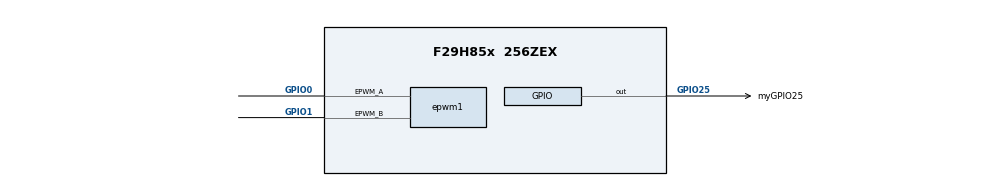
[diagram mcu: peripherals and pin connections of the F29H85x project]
/**
 * @cliArgs --device "F29H85x" --package "256ZEX" --part "F29H85x_256ZEX" --context "CPU1" --product "MCU_SDK_F29H85x@1.02.02.00"
 * @versions {"tool":"1.25.0+4237"}
 */

    
const divider15       = system.clockTree["PLL_REFDIV"];
divider15.divideValue = 1;

const multiplier1         = system.clockTree["PLL_IMULT"];
multiplier1.multiplyValue = 40;

const mux7       = system.clockTree["OSCCLKSRCSEL"];
mux7.inputSelect = "INTOSC2";

const epwm             = scripting.addModule("/driverlib/epwm.js", {}, false);
const epwm1            = epwm.addInstance();
const epwmxbar         = scripting.addModule("/driverlib/epwmxbar.js", {}, false);
const epwmxbar1        = epwmxbar.addInstance();
const gpio             = scripting.addModule("/driverlib/gpio.js", {}, false);
const gpio1            = gpio.addInstance();
const inputxbar_input  = scripting.addModule("/driverlib/inputxbar_input.js", {}, false);
const inputxbar_input1 = inputxbar_input.addInstance();

/**
 * Write custom configuration values to the imported modules.
 */
epwm1.$name                                                           = "myEPWM1";
epwm1.epwmTimebase_clockDiv                                           = "EPWM_CLOCK_DIVIDER_4";
epwm1.epwmTimebase_hsClockDiv                                         = "EPWM_HSCLOCK_DIVIDER_4";
epwm1.epwmTimebase_period                                             = 12000;
epwm1.epwmTimebase_counterMode                                        = "EPWM_COUNTER_MODE_UP_DOWN";
epwm1.epwmCounterCompare_cmpA                                         = 2000;
epwm1.epwmActionQualifier_EPWM_AQ_OUTPUT_A_ON_TIMEBASE_UP_CMPA        = "EPWM_AQ_OUTPUT_HIGH";
epwm1.epwmActionQualifier_EPWM_AQ_OUTPUT_A_ON_TIMEBASE_DOWN_CMPA      = "EPWM_AQ_OUTPUT_LOW";
epwm1.epwmActionQualifier_EPWM_AQ_OUTPUT_B_ON_TIMEBASE_UP_CMPA        = "EPWM_AQ_OUTPUT_HIGH";
epwm1.epwmActionQualifier_EPWM_AQ_OUTPUT_B_ON_TIMEBASE_DOWN_CMPA      = "EPWM_AQ_OUTPUT_LOW";
epwm1.epwmEventTrigger_enableInterrupt                                = true;
epwm1.epwmEventTrigger_registerInterrupts                             = true;
epwm1.epwmInt.interruptHandler                                        = "epwm1ISR";
epwm1.epwmEventTrigger_interruptSource                                = "EPWM_INT_TBCTR_ZERO";
epwm1.epwmEventTrigger_interruptEventCount                            = "3";
epwm1.epwmTripZone_cbcSource                                          = ["EPWM_TZ_SIGNAL_DCBEVT2"];
epwm1.epwmDigitalCompare_EPWM_TZ_DC_OUTPUT_B2                         = "EPWM_TZ_EVENT_DCXH_LOW";
epwm1.epwmDigitalCompare_dcFilterInput                                = "EPWM_DC_WINDOW_SOURCE_DCBEVT2";
epwm1.epwmDigitalCompare_useEdgeFilter                                = true;
epwm1.epwmDigitalCompare_edgeFilterEdgeCount                          = "EPWM_DC_EDGEFILT_EDGECNT_4";
epwm1.epwmDigitalCompare_enableValleyCapture                          = true;
epwm1.epwmDigitalCompare_valleyCaptureSource                          = "EPWM_VALLEY_TRIGGER_EVENT_CNTR_ZERO";
epwm1.epwmDigitalCompare_EPWM_DC_MODULE_B_EPWM_DC_EVENT_2_eventSource = "EPWM_DC_EVENT_SOURCE_FILT_SIGNAL";
epwm1.epwmDigitalCompare_EPWM_DC_MODULE_B_EPWM_DC_EVENT_2_eventSync   = "EPWM_DC_EVENT_INPUT_NOT_SYNCED";
epwm1.epwmTripZone_EPWM_TZ_ACTION_EVENT_TZA                           = "EPWM_TZ_ACTION_DISABLE";
epwm1.epwmTripZone_EPWM_TZ_ACTION_EVENT_TZB                           = "EPWM_TZ_ACTION_LOW";
epwm1.epwmDigitalCompare_EPWM_DC_TYPE_DCAH                            = "EPWM_DC_TRIP_TRIPIN2";
epwm1.epwmDigitalCompare_EPWM_DC_TYPE_DCAL                            = "EPWM_DC_TRIP_TRIPIN2";
epwm1.epwmDigitalCompare_EPWM_DC_TYPE_DCBH                            = "EPWM_DC_TRIP_TRIPIN2";
epwm1.epwmDigitalCompare_EPWM_DC_TYPE_DCBL                            = "EPWM_DC_TRIP_TRIPIN2";
epwm1.epwm.$assign                                                    = "EPWM1";
epwm1.epwm.epwm_aPin.$assign                                          = "GPIO0";
epwm1.epwm.epwm_bPin.$assign                                          = "GPIO1";

epwmxbar1.$name         = "myEPWMXBAR0";
epwmxbar1.sourceSignals = ["INPUTXBAR_INPUT1"];
epwmxbar1.tripInput     = "XBAR_TRIP2";

gpio1.$name           = "myGPIO25";
gpio1.direction       = "GPIO_DIR_MODE_OUT";
gpio1.qualMode        = "GPIO_QUAL_ASYNC";
gpio1.gpioPin.$assign = "GPIO25";

inputxbar_input1.$name         = "myINPUTXBARINPUT0";
inputxbar_input1.inputxbarGpio = "GPIO25";
